# pwrseq_me11 register map
Registers are access not given, no defined reset value unless marked. A register's access mark holds for its fields unless they carry their own. Offsets are from the block's base; lines under a group give offsets from that group; [hi:lo] are bit positions; {n}, {i} and the like mark numbered series; 'fields as' and 'values as' point back to an identical list; <NAME> marks a mode.

## Memory map
0x40006800 PWRSEQ size 0x800 — Power Sequencer / Low Power Control Register.

## PWRSEQ — Power Sequencer / Low Power Control Register.
Base 0x40006800
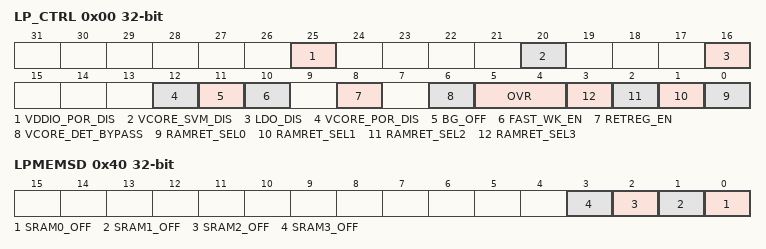
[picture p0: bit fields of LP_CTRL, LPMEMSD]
0x00 LP_CTRL — Low Power Control Register.
  [25] VDDIO_POR_DIS — VDDIO Power-On Reset Monitor Disable. This bit controls the Power-On Reset monitor on VDDIO supply in all operating mods.
    0=en (Enabled.); 1=dis (Disabled.)
  [20] VCORE_SVM_DIS — V CORE Supply Voltage Monitor Disable
    0=en (Enable if Bandgap is ON(default)); 1=dis (Disabled.)
  [16] LDO_DIS — LDO Disable
    0=en (Enable if Bandgap is ON(default)); 1=dis (Disabled.)
  [12] VCORE_POR_DIS — V CORE POR Disable for DEEPSLEEP and BACKUP Mode
    0=dis (Disabled.); 1=en (Enabled.)
  [11] BG_OFF — Band Gap Disable for DEEPSLEEP and BACKUP Mode
    0=on (Bandgap is always ON.); 1=off (Bandgap is OFF in DeepSleep mode(default).)
  [10] FAST_WK_EN — Fast Wake-Up Mode. This bit enables fast wake-up from DeepSleep mode.
    0=dis (Disabled.); 1=en (Enabled.)
  [8] RETREG_EN — Retention Regulator Enable. This bit controls the retention regulator in BACKUP mode.
    0=dis (Disabled.); 1=en (Enabled.)
  [6] VCORE_DET_BYPASS — Bypass V CORE External Supply Detection
    0=enabled; 1=Disable
  [5:4] OVR — Operating Voltage Range
    0=0_9V (0.9V 24MHz); 1=1_0V (1.0V 48MHz); 2=1_1V (1.1V 96MHz)
  [n] RAMRET_SEL{n} (n=0..3) — System RAM {n} Data retention in BACKUP mode.
    0=dis (Disabled.); 1=en (Enabled.)
0x04 LP_WAKEFL — Low Power Mode Wakeup Flags for GPIO0
  [13:0] WAKEST — Wakeup IRQ flags (write ones to clear). One or more of these bits will be set when the corresponding dedicated GPIO pin(s) transition(s) from low to high or high to low. If GPIO wakeup source is selected, using PM.GPIOWKEN register, and the corresponding bit is also selected in LPWKEN register, an interrupt will be gnerated to wake up the CPU from a low power mode.
0x08 LPWK_EN — Low Power I/O Wakeup Enable Register 0. This register enables low power wakeup functionality for GPIO0.
  [13:0] WAKEEN — Enable wakeup. These bits allow wakeup from the corresponding GPIO pin(s) on transition(s) from low to high or high to low when PM.GPIOWKEN is set. Wakeup status is indicated in PPWKST register.
0x40 LPMEMSD — Low Power Memory Shutdown Control.
  [all] fields
    0=Normal Operating Mode; 1=Shutdown Mode
  [n] SRAM{n}_OFF (n=0..3) — System RAM block {n} Shut Down.
